# COMPUTE_CLUSTER0_A72SS0_CORE0_ECC_AGGR_MPU0_CORE0_ECC_AGGR register map
Vendor: Texas Instruments
Peripheral module from a debugger description file (folder J721S2).
Registers are 32-bit, access not given, reset 0x0 unless marked. A register's access mark holds for its fields unless they carry their own. Offsets are as the file gives them; lines under a group give offsets from that group; [hi:lo] are bit positions; {n}, {i} and the like mark numbered series; 'fields as' and 'values as' point back to an identical list; <NAME> marks a mode.

## COMPUTE_CLUSTER0_A72SS0_CORE0_ECC_AGGR_MPU0_CORE0_ECC_AGGR
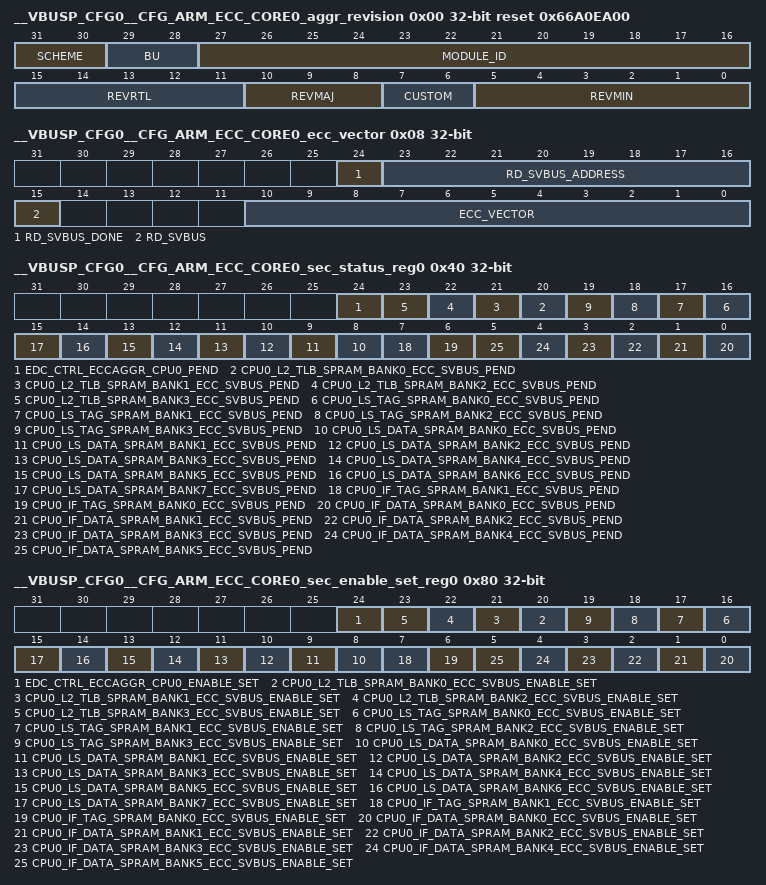
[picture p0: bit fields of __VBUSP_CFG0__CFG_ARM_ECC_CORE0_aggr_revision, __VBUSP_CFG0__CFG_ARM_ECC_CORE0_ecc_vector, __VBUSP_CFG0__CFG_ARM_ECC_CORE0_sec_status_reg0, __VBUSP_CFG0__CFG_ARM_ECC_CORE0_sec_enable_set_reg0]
0x00 __VBUSP_CFG0__CFG_ARM_ECC_CORE0_aggr_revision ro reset 0x66A0EA00 — Revision parameters
  [31:30] SCHEME
  [29:28] BU
  [27:16] MODULE_ID
  [15:11] REVRTL — RTL version
  [10:8] REVMAJ — Major version
  [7:6] CUSTOM — Custom version
  [5:0] REVMIN — Minor version
0x08 __VBUSP_CFG0__CFG_ARM_ECC_CORE0_ecc_vector — ECC Vector Register
  [24] RD_SVBUS_DONE — Status to indicate if read on serial VBUS is complete, write of any value will clear this bit. (access R/W1TC)
  [23:16] RD_SVBUS_ADDRESS rw — Read address
  [15] RD_SVBUS — Write 1 to trigger a read on the serial VBUS (access R/W1TS)
  [10:0] ECC_VECTOR rw — Value written to select the corresponding ECC RAM for control or status
0x0C __VBUSP_CFG0__CFG_ARM_ECC_CORE0_misc_status ro reset 0x19 — Misc Status
  [10:0] NUM_RAMS — Indicates the number of RAMS serviced by the ECC aggregator
0x10 __VBUSP_CFG0__CFG_ARM_ECC_CORE0_reserved_svbus rw — Reference other documents that contain the ECC RAM wrapper and EDC controller serial vbus register sets.
  [31:0] DATA — Serial VBUS register data
0x3C __VBUSP_CFG0__CFG_ARM_ECC_CORE0_sec_eoi_reg — EOI Register
  [0] EOI_WR — EOI Register (access R/W1TS)
0x40 __VBUSP_CFG0__CFG_ARM_ECC_CORE0_sec_status_reg0 — Interrupt Status Register 0
  [24] EDC_CTRL_ECCAGGR_CPU0_PEND — Interrupt Pending Status for edc_ctrl_eccaggr_cpu0_pend (access R/W1TS)
  [n+20] CPU0_L2_TLB_SPRAM_BANK{n}_ECC_SVBUS_PEND (n=0..3) — Interrupt Pending Status for cpu0_l2_tlb_spram_bank{n}_ecc_svbus_pend (access R/W1TS)
  [n+16] CPU0_LS_TAG_SPRAM_BANK{n}_ECC_SVBUS_PEND (n=0..3) — Interrupt Pending Status for cpu0_ls_tag_spram_bank{n}_ecc_svbus_pend (access R/W1TS)
  [n+8] CPU0_LS_DATA_SPRAM_BANK{n}_ECC_SVBUS_PEND (n=0..7) — Interrupt Pending Status for cpu0_ls_data_spram_bank{n}_ecc_svbus_pend (access R/W1TS)
  [7] CPU0_IF_TAG_SPRAM_BANK1_ECC_SVBUS_PEND — Interrupt Pending Status for cpu0_if_tag_spram_bank1_ecc_svbus_pend (access R/W1TS)
  [6] CPU0_IF_TAG_SPRAM_BANK0_ECC_SVBUS_PEND — Interrupt Pending Status for cpu0_if_tag_spram_bank0_ecc_svbus_pend (access R/W1TS)
  [n] CPU0_IF_DATA_SPRAM_BANK{n}_ECC_SVBUS_PEND (n=0..5) — Interrupt Pending Status for cpu0_if_data_spram_bank{n}_ecc_svbus_pend (access R/W1TS)
0x80 __VBUSP_CFG0__CFG_ARM_ECC_CORE0_sec_enable_set_reg0 — Interrupt Enable Set Register 0
  [24] EDC_CTRL_ECCAGGR_CPU0_ENABLE_SET — Interrupt Enable Set Register for edc_ctrl_eccaggr_cpu0_pend (access R/W1TS)
  [n+20] CPU0_L2_TLB_SPRAM_BANK{n}_ECC_SVBUS_ENABLE_SET (n=0..3) — Interrupt Enable Set Register for cpu0_l2_tlb_spram_bank{n}_ecc_svbus_pend (access R/W1TS)
  [n+16] CPU0_LS_TAG_SPRAM_BANK{n}_ECC_SVBUS_ENABLE_SET (n=0..3) — Interrupt Enable Set Register for cpu0_ls_tag_spram_bank{n}_ecc_svbus_pend (access R/W1TS)
  [n+8] CPU0_LS_DATA_SPRAM_BANK{n}_ECC_SVBUS_ENABLE_SET (n=0..7) — Interrupt Enable Set Register for cpu0_ls_data_spram_bank{n}_ecc_svbus_pend (access R/W1TS)
  [7] CPU0_IF_TAG_SPRAM_BANK1_ECC_SVBUS_ENABLE_SET — Interrupt Enable Set Register for cpu0_if_tag_spram_bank1_ecc_svbus_pend (access R/W1TS)
  [6] CPU0_IF_TAG_SPRAM_BANK0_ECC_SVBUS_ENABLE_SET — Interrupt Enable Set Register for cpu0_if_tag_spram_bank0_ecc_svbus_pend (access R/W1TS)
  [n] CPU0_IF_DATA_SPRAM_BANK{n}_ECC_SVBUS_ENABLE_SET (n=0..5) — Interrupt Enable Set Register for cpu0_if_data_spram_bank{n}_ecc_svbus_pend (access R/W1TS)
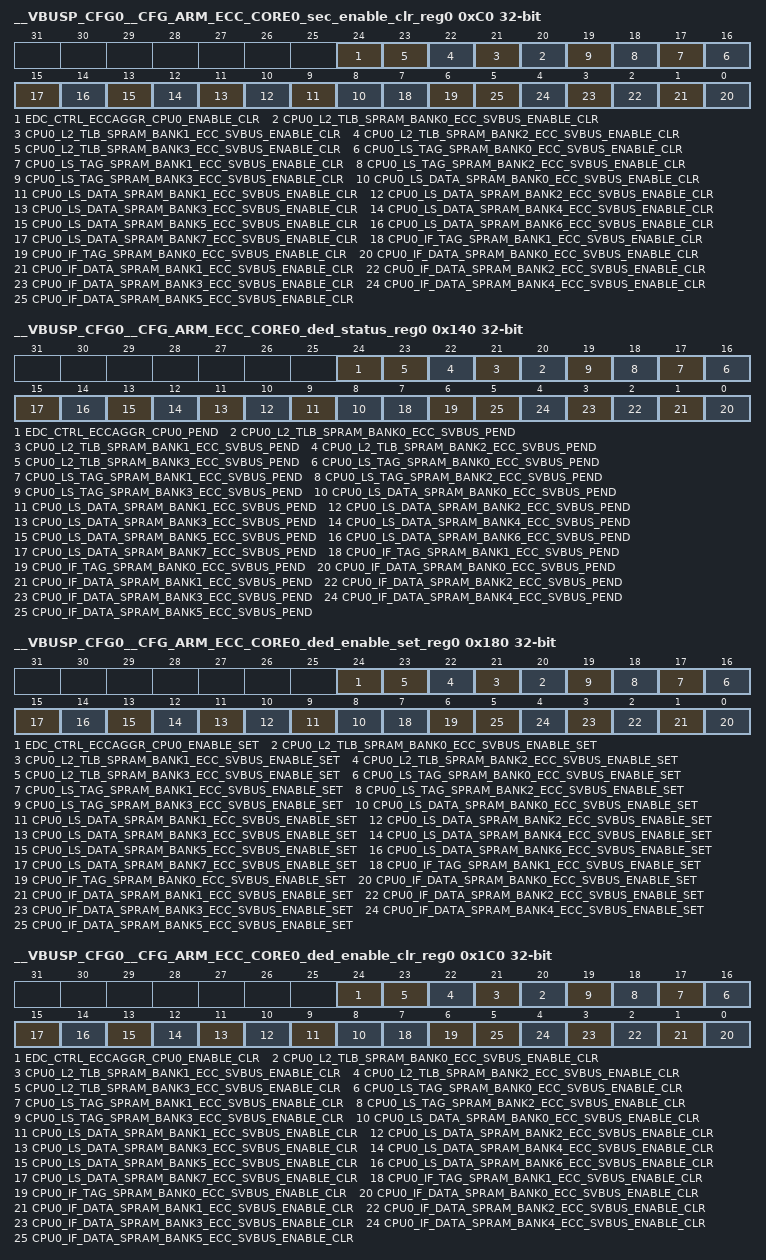
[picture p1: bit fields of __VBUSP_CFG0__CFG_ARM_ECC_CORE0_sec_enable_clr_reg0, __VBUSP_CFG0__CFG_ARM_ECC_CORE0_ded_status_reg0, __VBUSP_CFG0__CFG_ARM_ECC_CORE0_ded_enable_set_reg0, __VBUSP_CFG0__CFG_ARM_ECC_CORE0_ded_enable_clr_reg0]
0xC0 __VBUSP_CFG0__CFG_ARM_ECC_CORE0_sec_enable_clr_reg0 — Interrupt Enable Clear Register 0
  [24] EDC_CTRL_ECCAGGR_CPU0_ENABLE_CLR — Interrupt Enable Clear Register for edc_ctrl_eccaggr_cpu0_pend (access R/W1TC)
  [n+20] CPU0_L2_TLB_SPRAM_BANK{n}_ECC_SVBUS_ENABLE_CLR (n=0..3) — Interrupt Enable Clear Register for cpu0_l2_tlb_spram_bank{n}_ecc_svbus_pend (access R/W1TC)
  [n+16] CPU0_LS_TAG_SPRAM_BANK{n}_ECC_SVBUS_ENABLE_CLR (n=0..3) — Interrupt Enable Clear Register for cpu0_ls_tag_spram_bank{n}_ecc_svbus_pend (access R/W1TC)
  [n+8] CPU0_LS_DATA_SPRAM_BANK{n}_ECC_SVBUS_ENABLE_CLR (n=0..7) — Interrupt Enable Clear Register for cpu0_ls_data_spram_bank{n}_ecc_svbus_pend (access R/W1TC)
  [7] CPU0_IF_TAG_SPRAM_BANK1_ECC_SVBUS_ENABLE_CLR — Interrupt Enable Clear Register for cpu0_if_tag_spram_bank1_ecc_svbus_pend (access R/W1TC)
  [6] CPU0_IF_TAG_SPRAM_BANK0_ECC_SVBUS_ENABLE_CLR — Interrupt Enable Clear Register for cpu0_if_tag_spram_bank0_ecc_svbus_pend (access R/W1TC)
  [n] CPU0_IF_DATA_SPRAM_BANK{n}_ECC_SVBUS_ENABLE_CLR (n=0..5) — Interrupt Enable Clear Register for cpu0_if_data_spram_bank{n}_ecc_svbus_pend (access R/W1TC)
0x13C __VBUSP_CFG0__CFG_ARM_ECC_CORE0_ded_eoi_reg — EOI Register
  [0] EOI_WR — EOI Register (access R/W1TS)
0x140 __VBUSP_CFG0__CFG_ARM_ECC_CORE0_ded_status_reg0 — Interrupt Status Register 0
  fields as __VBUSP_CFG0__CFG_ARM_ECC_CORE0_sec_status_reg0
0x180 __VBUSP_CFG0__CFG_ARM_ECC_CORE0_ded_enable_set_reg0 — Interrupt Enable Set Register 0
  fields as __VBUSP_CFG0__CFG_ARM_ECC_CORE0_sec_enable_set_reg0
0x1C0 __VBUSP_CFG0__CFG_ARM_ECC_CORE0_ded_enable_clr_reg0 — Interrupt Enable Clear Register 0
  fields as __VBUSP_CFG0__CFG_ARM_ECC_CORE0_sec_enable_clr_reg0
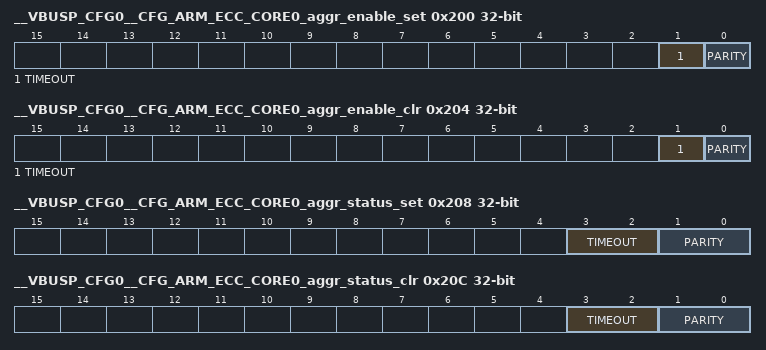
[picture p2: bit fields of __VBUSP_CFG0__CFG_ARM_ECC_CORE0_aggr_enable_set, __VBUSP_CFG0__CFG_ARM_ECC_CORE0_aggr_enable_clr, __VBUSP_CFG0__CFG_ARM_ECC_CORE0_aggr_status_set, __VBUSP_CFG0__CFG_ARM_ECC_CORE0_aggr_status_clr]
0x200 __VBUSP_CFG0__CFG_ARM_ECC_CORE0_aggr_enable_set — AGGR interrupt enable set Register
  [1] TIMEOUT — interrupt enable set for svbus timeout errors (access R/W1TS)
  [0] PARITY — interrupt enable set for parity errors (access R/W1TS)
0x204 __VBUSP_CFG0__CFG_ARM_ECC_CORE0_aggr_enable_clr — AGGR interrupt enable clear Register
  [1] TIMEOUT — interrupt enable clear for svbus timeout errors (access R/W1TC)
  [0] PARITY — interrupt enable clear for parity errors (access R/W1TC)
0x208 __VBUSP_CFG0__CFG_ARM_ECC_CORE0_aggr_status_set — AGGR interrupt status set Register
  [3:2] TIMEOUT — interrupt status set for svbus timeout errors (access R/WI)
  [1:0] PARITY — interrupt status set for parity errors (access R/WI)
0x20C __VBUSP_CFG0__CFG_ARM_ECC_CORE0_aggr_status_clr — AGGR interrupt status clear Register
  [3:2] TIMEOUT — interrupt status clear for svbus timeout errors (access R/WD)
  [1:0] PARITY — interrupt status clear for parity errors (access R/WD)
